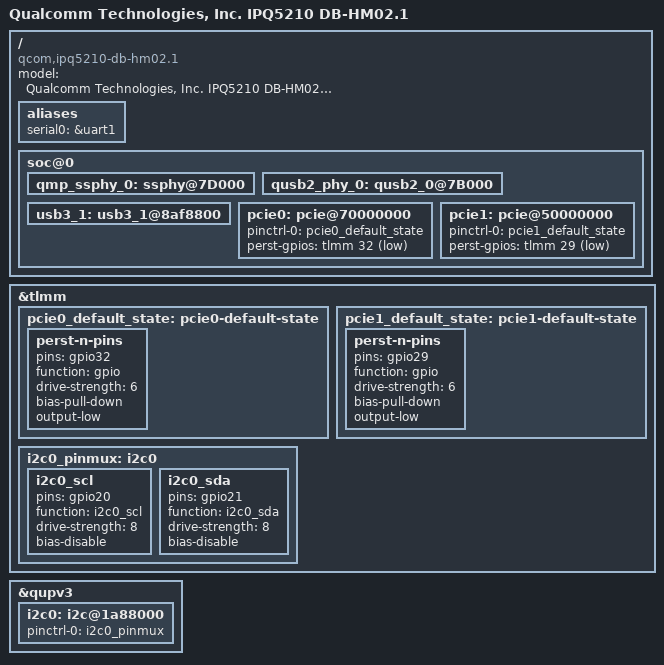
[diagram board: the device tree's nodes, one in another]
// SPDX-License-Identifier: GPL-2.0-only
/*
 * Copyright (c) Qualcomm Technologies, Inc. and/or its subsidiaries.
 */

/dts-v1/;

#include "ipq5210-u-boot.dtsi"

/ {
	model = "Qualcomm Technologies, Inc. IPQ5210 DB-HM02.1";
	compatible = "qcom,ipq5210-db-hm02.1", "qcom,ipq5210";

	aliases {
		serial0 = &uart1;
	};

	soc@0 {
		qmp_ssphy_0: ssphy@7D000 {
			status = "okay";
		};

		qusb2_phy_0: qusb2_0@7B000 {
			status = "okay";
		};

		usb3_1: usb3_1@8af8800 {
			status = "okay";
		};

		pcie0: pcie@70000000 {
			pinctrl-0 = <&pcie0_default_state>;
			pinctrl-names = "default";
			perst-gpios = <&tlmm 32 GPIO_ACTIVE_LOW>;
			status = "okay";
		};

		pcie1: pcie@50000000 {
			pinctrl-0 = <&pcie1_default_state>;
			pinctrl-names = "default";
			perst-gpios = <&tlmm 29 GPIO_ACTIVE_LOW>;
			status = "okay";
		};
	};
};

&tlmm {
	pcie0_default_state: pcie0-default-state {
		perst-n-pins {
			pins = "gpio32";
			function = "gpio";
			drive-strength = <6>;
			bias-pull-down;
			output-low;
		};
	};

	pcie1_default_state: pcie1-default-state {
		perst-n-pins {
			pins = "gpio29";
			function = "gpio";
			drive-strength = <6>;
			bias-pull-down;
			output-low;
		};
	};

	i2c0_pinmux: i2c0 {
		i2c0_scl {
			pins = "gpio20";
			function = "i2c0_scl";
			drive-strength = <8>;
			bias-disable;
		};

		i2c0_sda {
			pins = "gpio21";
			function = "i2c0_sda";
			drive-strength = <8>;
			bias-disable;
		};
	};
};

&qupv3 {
	i2c0: i2c@1a88000 {
		pinctrl-0 = <&i2c0_pinmux>;
		pinctrl-names = "default";
		status = "okay";
	};
};
